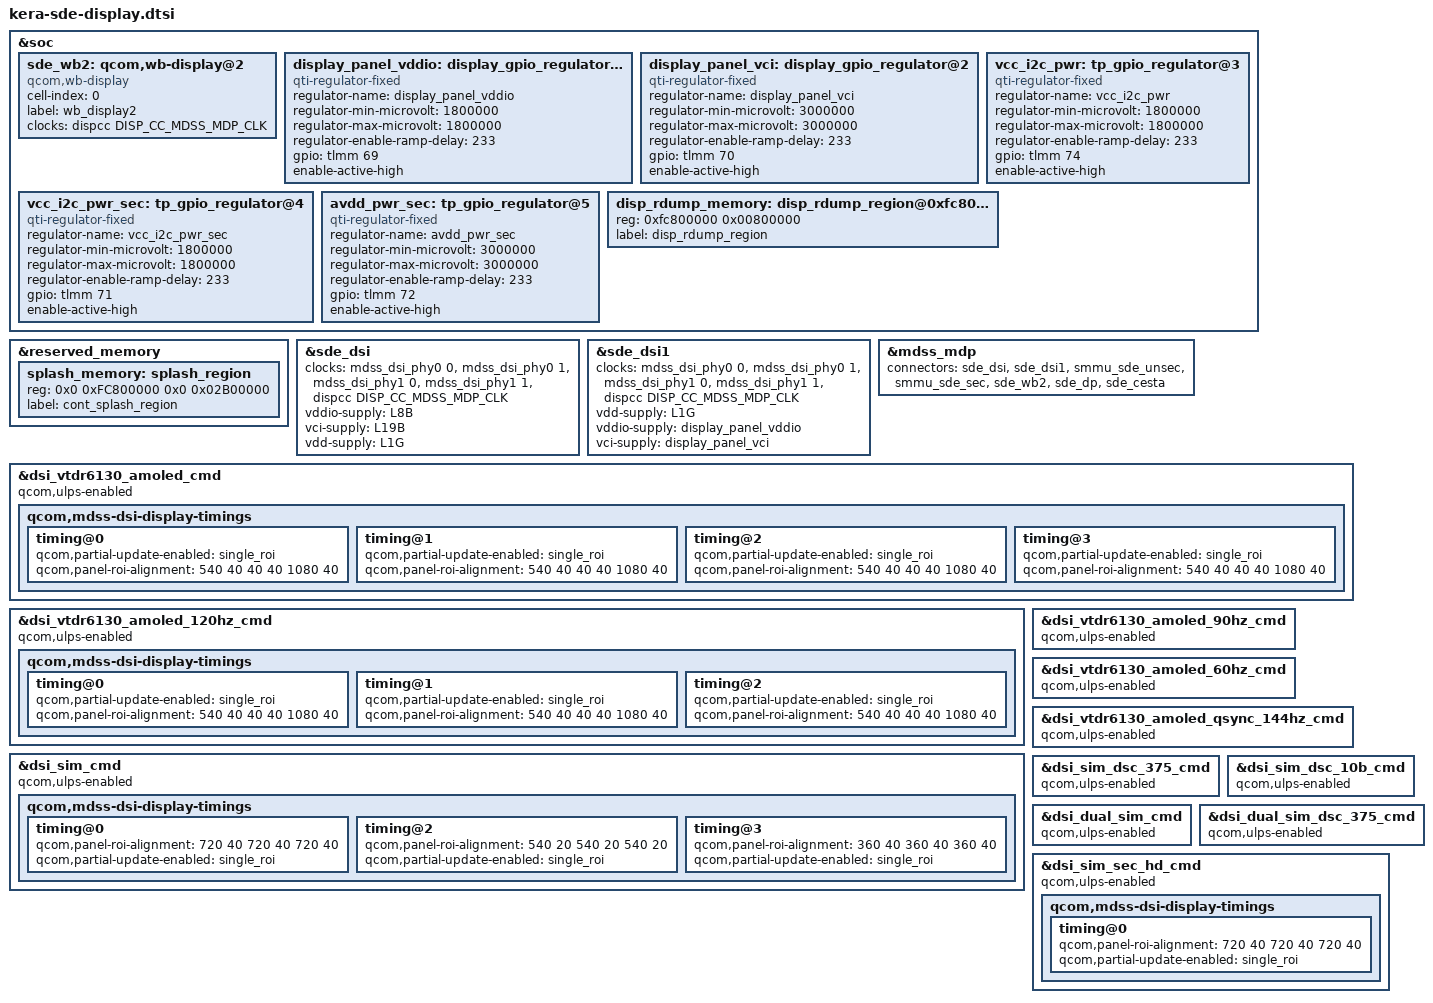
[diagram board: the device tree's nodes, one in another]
// SPDX-License-Identifier: BSD-3-Clause
/*
 * Copyright (c) Qualcomm Technologies, Inc. and/or its subsidiaries.
 */

#include <dt-bindings/clock/qcom,dispcc-tuna.h>
#include "kera-sde-display-common.dtsi"

&soc {
	sde_wb2: qcom,wb-display@2 {
		compatible = "qcom,wb-display";
		cell-index = <0>;
		label = "wb_display2";
		clocks = <&dispcc DISP_CC_MDSS_MDP_CLK>;
		clock-names = "mdp_core_clk";
	};
	
	display_panel_vddio: display_gpio_regulator@1 {
               compatible = "qti-regulator-fixed";
               regulator-name = "display_panel_vddio";
               regulator-min-microvolt = <1800000>;
               regulator-max-microvolt = <1800000>;
               regulator-enable-ramp-delay = <233>;
               gpio = <&tlmm 69 0>;
               enable-active-high;
            //    regulator-boot-on;
            //    proxy-supply = <&display_panel_vddio>;
            //    qcom,proxy-consumer-enable;
               pinctrl-names = "default";
       };

      display_panel_vci: display_gpio_regulator@2 {
               compatible = "qti-regulator-fixed";
               regulator-name = "display_panel_vci";
               regulator-min-microvolt = <3000000>;
               regulator-max-microvolt = <3000000>;
               regulator-enable-ramp-delay = <233>;
               gpio = <&tlmm 70 0>;
               enable-active-high;
               // regulator-boot-on;
               // proxy-supply = <&display_panel_vci>;
               // qcom,proxy-consumer-enable;
               pinctrl-names = "default";
       };

	   vcc_i2c_pwr: tp_gpio_regulator@3 {
               compatible = "qti-regulator-fixed";
               regulator-name = "vcc_i2c_pwr";
               regulator-min-microvolt = <1800000>;
               regulator-max-microvolt = <1800000>;
               regulator-enable-ramp-delay = <233>;
               gpio = <&tlmm 74 0>;
               enable-active-high;
            //    regulator-boot-on;
            //    proxy-supply = <&vcc_i2c_pwr>;
            //    qcom,proxy-consumer-enable;
               pinctrl-names = "default";
       };
	   vcc_i2c_pwr_sec: tp_gpio_regulator@4 {
               compatible = "qti-regulator-fixed";
               regulator-name = "vcc_i2c_pwr_sec";
               regulator-min-microvolt = <1800000>;
               regulator-max-microvolt = <1800000>;
               regulator-enable-ramp-delay = <233>;
               gpio = <&tlmm 71 0>;
               enable-active-high;
            //    regulator-boot-on;
            //    proxy-supply = <&vcc_i2c_pwr_sec>;
            //    qcom,proxy-consumer-enable;
               pinctrl-names = "default";
       };

	   avdd_pwr_sec: tp_gpio_regulator@5 {
               compatible = "qti-regulator-fixed";
               regulator-name = "avdd_pwr_sec";
               regulator-min-microvolt = <3000000>;
               regulator-max-microvolt = <3000000>;
               regulator-enable-ramp-delay = <233>;
               gpio = <&tlmm 72 0>;
               enable-active-high;
            //    regulator-boot-on;
            //    proxy-supply = <&avdd_pwr_sec>;
            //    qcom,proxy-consumer-enable;
               pinctrl-names = "default";
       };

	disp_rdump_memory: disp_rdump_region@0xfc800000 {
		reg = <0xfc800000 0x00800000>;
		label = "disp_rdump_region";
	};
};

&reserved_memory {
	splash_memory: splash_region {
		reg = <0x0 0xFC800000 0x0 0x02B00000>;
		label = "cont_splash_region";
	};
};

&sde_dsi {
	clocks = <&mdss_dsi_phy0 0>,
		 <&mdss_dsi_phy0 1>,
		 <&mdss_dsi_phy1 0>,
		 <&mdss_dsi_phy1 1>,
		 /*
		  * Currently the dsi clock handles are under the dsi
		  * controller DT node. As soon as the controller probe
		  * finishes, the dispcc sync state can get called before
		  * the dsi_display probe potentially disturbing the clock
		  * votes for cont_splash use case. Hence we are no longer
		  * protected by the component model in this case against the
		  * disp cc sync state getting triggered after the dsi_ctrl
		  * probe. To protect against this incorrect sync state trigger
		  * add this dummy MDP clk vote handle to the dsi_display
		  * DT node. Since the dsi_display driver does not parse
		  * MDP clock nodes, no actual vote shall be added and this
		  * change is done just to satisfy sync state requirements.
		  */
		 <&dispcc DISP_CC_MDSS_MDP_CLK>;
	clock-names = "pll_byte_clk0", "pll_dsi_clk0",
		      "pll_byte_clk1", "pll_dsi_clk1",
		      "mdp_core_clk";

	vddio-supply = <&L8B>;
	vci-supply = <&L19B>;
	vdd-supply = <&L1G>;
};

&sde_dsi1 {
	clocks = <&mdss_dsi_phy0 0>,
		 <&mdss_dsi_phy0 1>,
		 <&mdss_dsi_phy1 0>,
		 <&mdss_dsi_phy1 1>,
		 /*
		  * Currently the dsi clock handles are under the dsi
		  * controller DT node. As soon as the controller probe
		  * finishes, the dispcc sync state can get called before
		  * the dsi_display probe potentially disturbing the clock
		  * votes for cont_splash use case. Hence we are no longer
		  * protected by the component model in this case against the
		  * disp cc sync state getting triggered after the dsi_ctrl
		  * probe. To protect against this incorrect sync state trigger
		  * add this dummy MDP clk vote handle to the dsi_display
		  * DT node. Since the dsi_display driver does not parse
		  * MDP clock nodes, no actual vote shall be added and this
		  * change is done just to satisfy sync state requirements.
		  */
		 <&dispcc DISP_CC_MDSS_MDP_CLK>;
	clock-names = "pll_byte_clk0", "pll_dsi_clk0",
		      "pll_byte_clk1", "pll_dsi_clk1",
		      "mdp_core_clk";

	//vddio-supply = <&L8B>;
	//vci-supply = <&L19B>;
	vdd-supply = <&L1G>;
	vddio-supply = <&display_panel_vddio>;  //69
	vci-supply = <&display_panel_vci>;   //70
};

&mdss_mdp {
	connectors = <&sde_dsi &sde_dsi1 &smmu_sde_unsec &smmu_sde_sec &sde_wb2 &sde_dp
			&sde_cesta>;
};

&dsi_vtdr6130_amoled_cmd {
	qcom,ulps-enabled;
	qcom,mdss-dsi-display-timings {
		timing@0 {
			qcom,partial-update-enabled = "single_roi";
			qcom,panel-roi-alignment = <540 40 40 40 1080 40>;
		};

		timing@1 {
			qcom,partial-update-enabled = "single_roi";
			qcom,panel-roi-alignment = <540 40 40 40 1080 40>;
		};

		timing@2 {
			qcom,partial-update-enabled = "single_roi";
			qcom,panel-roi-alignment = <540 40 40 40 1080 40>;
		};

		timing@3 {
			qcom,partial-update-enabled = "single_roi";
			qcom,panel-roi-alignment = <540 40 40 40 1080 40>;
		};
	};
};

&dsi_vtdr6130_amoled_120hz_cmd {
	qcom,ulps-enabled;
	qcom,mdss-dsi-display-timings {
		timing@0 {
			qcom,partial-update-enabled = "single_roi";
			qcom,panel-roi-alignment = <540 40 40 40 1080 40>;
		};

		timing@1 {
			qcom,partial-update-enabled = "single_roi";
			qcom,panel-roi-alignment = <540 40 40 40 1080 40>;
		};

		timing@2 {
			qcom,partial-update-enabled = "single_roi";
			qcom,panel-roi-alignment = <540 40 40 40 1080 40>;
		};
	};
};

&dsi_vtdr6130_amoled_90hz_cmd {
	qcom,ulps-enabled;
};

&dsi_vtdr6130_amoled_60hz_cmd {
	qcom,ulps-enabled;
};

&dsi_vtdr6130_amoled_qsync_144hz_cmd {
	qcom,ulps-enabled;
};

&dsi_sim_cmd {
	qcom,ulps-enabled;
	qcom,mdss-dsi-display-timings {
		timing@0 { /* WQHD 60FPS cmd vid mode*/
			qcom,panel-roi-alignment = <720 40 720 40 720 40>;
			qcom,partial-update-enabled = "single_roi";
		};

		timing@2 { /* FHD 60FPS cmd mode*/
			qcom,panel-roi-alignment = <540 20 540 20 540 20>;
			qcom,partial-update-enabled = "single_roi";
		};

		timing@3 { /* HD 60FPS cmd mode*/
			qcom,panel-roi-alignment = <360 40 360 40 360 40>;
			qcom,partial-update-enabled = "single_roi";
		};
	};
};

&dsi_sim_dsc_375_cmd {
	qcom,ulps-enabled;
};

&dsi_sim_dsc_10b_cmd {
	qcom,ulps-enabled;
};

&dsi_dual_sim_cmd {
	qcom,ulps-enabled;
};

&dsi_dual_sim_dsc_375_cmd {
	qcom,ulps-enabled;
};

&dsi_sim_sec_hd_cmd {
	qcom,ulps-enabled;
	qcom,mdss-dsi-display-timings {
		timing@0 {
			qcom,panel-roi-alignment = <720 40 720 40 720 40>;
			qcom,partial-update-enabled = "single_roi";
		};
	};
};
